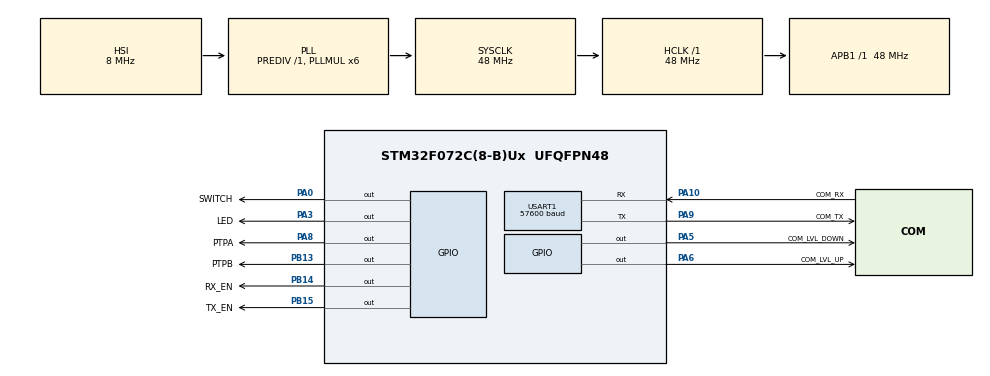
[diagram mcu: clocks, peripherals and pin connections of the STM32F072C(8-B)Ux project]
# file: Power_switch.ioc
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Mcu.Family=STM32F0
Mcu.Name=STM32F072C(8-B)Ux
Mcu.Package=UFQFPN48
NVIC.EXTI4_15_IRQn=true\:0\:0\:false\:false\:true\:true\:true
NVIC.USART1_IRQn=true\:0\:0\:false\:false\:false\:true\:true
PA0.GPIO_Label=SWITCH
PA0.Signal=GPIO_Output
PA10.GPIO_Label=COM_RX
PA10.GPIO_PuPd=GPIO_PULLUP
PA10.Mode=Asynchronous
PA10.Signal=USART1_RX
PA2.GPIO_Label=POWER_SENSOR
PA2.Signal=ADC_IN2
PA3.GPIO_Label=LED
PA3.PinState=GPIO_PIN_SET
PA3.Signal=GPIO_Output
PA5.GPIO_Label=COM_LVL_DOWN
PA5.GPIO_PuPd=GPIO_PULLUP
PA5.PinState=GPIO_PIN_RESET
PA5.Signal=GPIO_Output
PA6.GPIO_Label=COM_LVL_UP
PA6.GPIO_PuPd=GPIO_PULLDOWN
PA6.PinState=GPIO_PIN_SET
PA6.Signal=GPIO_Output
PA8.GPIO_Label=PTPA
PA8.GPIO_ModeDefaultEXTI=GPIO_MODE_IT_FALLING
PA8.GPIO_PuPd=GPIO_PULLUP
PA8.Signal=SharedStack_PA8
PA8.Stacked=true
PA9.GPIO_Label=COM_TX
PA9.GPIO_PuPd=GPIO_PULLUP
PA9.Mode=Asynchronous
PA9.Signal=USART1_TX
PB13.GPIO_Label=PTPB
PB13.GPIO_ModeDefaultEXTI=GPIO_MODE_IT_FALLING
PB13.GPIO_PuPd=GPIO_PULLUP
PB13.Signal=SharedStack_PB13
PB13.Stacked=true
PB14.GPIO_Label=RX_EN
PB14.Signal=GPIO_Output
PB15.GPIO_Label=TX_EN
PB15.Signal=GPIO_Output
ProjectManager.HeapSize=0x200
ProjectManager.StackSize=0x400
ProjectManager.TargetToolchain=Other Toolchains (GPDSC)
RCC.AHBFreq_Value=48000000
RCC.APB1Freq_Value=48000000
RCC.APB1TimFreq_Value=48000000
RCC.HCLKFreq_Value=48000000
RCC.PLLMUL=RCC_PLL_MUL6
RCC.SYSCLKFreq_VALUE=48000000
RCC.SYSCLKSource=RCC_SYSCLKSOURCE_PLLCLK
SH.SharedStack_PA8.0=GPIO_Output+0
SH.SharedStack_PA8.1=GPIO_EXTI8
SH.SharedStack_PB13.0=GPIO_Output+0
SH.SharedStack_PB13.1=GPIO_EXTI13
USART1.BaudRate=57600
USART1.VirtualMode-Asynchronous=VM_ASYNC
board=custom

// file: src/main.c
/* USER CODE BEGIN Header */
/**
  ******************************************************************************
  * @file           : main.c
  * @brief          : Main program body
  ******************************************************************************
  * @attention
  *
  * <h2><center>&copy; Copyright (c) 2020 STMicroelectronics.
  * All rights reserved.</center></h2>
  *
  * This software component is licensed by ST under BSD 3-Clause license,
  * the "License"; You may not use this file except in compliance with the
  * License. You may obtain a copy of the License at:
  *                        opensource.org/licenses/BSD-3-Clause
  *
  ******************************************************************************
  */
/* USER CODE END Header */

#include "main.h"
#include "usart.h"
#include "gpio.h"

/* USER CODE BEGIN Includes */
#include "luos.h"
#include "power_switch.h"
/* USER CODE END Includes */

void SystemClock_Config(void);

int main(void)
{

  /* MCU Configuration--------------------------------------------------------*/

  /* Reset of all peripherals, Initializes the Flash interface and the Systick. */
  HAL_Init();

  /* Configure the system clock */
  SystemClock_Config();

  /* Initialize all configured peripherals */
  MX_GPIO_Init();
  MX_USART1_UART_Init();
  /* USER CODE BEGIN 2 */
  Luos_Init();
  PowerSwitch_Init();
  /* USER CODE END 2 */

  /* Infinite loop */
  /* USER CODE BEGIN WHILE */
  while (1)
  {
    Luos_Loop();
    PowerSwitch_Loop();
    /* USER CODE END WHILE */

  }
}

void SystemClock_Config(void)
{
  RCC_OscInitTypeDef RCC_OscInitStruct = {0};
  RCC_ClkInitTypeDef RCC_ClkInitStruct = {0};
  RCC_PeriphCLKInitTypeDef PeriphClkInit = {0};

  /** Initializes the CPU, AHB and APB busses clocks
  */
  RCC_OscInitStruct.OscillatorType = RCC_OSCILLATORTYPE_HSI;
  RCC_OscInitStruct.HSIState = RCC_HSI_ON;
  RCC_OscInitStruct.HSICalibrationValue = RCC_HSICALIBRATION_DEFAULT;
  RCC_OscInitStruct.PLL.PLLState = RCC_PLL_ON;
  RCC_OscInitStruct.PLL.PLLSource = RCC_PLLSOURCE_HSI;
  RCC_OscInitStruct.PLL.PLLMUL = RCC_PLL_MUL6;
  RCC_OscInitStruct.PLL.PREDIV = RCC_PREDIV_DIV1;
  if (HAL_RCC_OscConfig(&RCC_OscInitStruct) != HAL_OK)
  {
    Error_Handler();
  }
  /** Initializes the CPU, AHB and APB busses clocks
  */
  RCC_ClkInitStruct.ClockType = RCC_CLOCKTYPE_HCLK|RCC_CLOCKTYPE_SYSCLK
                              |RCC_CLOCKTYPE_PCLK1;
  RCC_ClkInitStruct.SYSCLKSource = RCC_SYSCLKSOURCE_PLLCLK;
  RCC_ClkInitStruct.AHBCLKDivider = RCC_SYSCLK_DIV1;
  RCC_ClkInitStruct.APB1CLKDivider = RCC_HCLK_DIV1;

  if (HAL_RCC_ClockConfig(&RCC_ClkInitStruct, FLASH_LATENCY_1) != HAL_OK)
  {
    Error_Handler();
  }
  PeriphClkInit.PeriphClockSelection = RCC_PERIPHCLK_USART1;
  PeriphClkInit.Usart1ClockSelection = RCC_USART1CLKSOURCE_PCLK1;
  if (HAL_RCCEx_PeriphCLKConfig(&PeriphClkInit) != HAL_OK)
  {
    Error_Handler();
  }
}

void Error_Handler(void)
{
}

/************************ (C) COPYRIGHT STMicroelectronics *****END OF FILE****/
